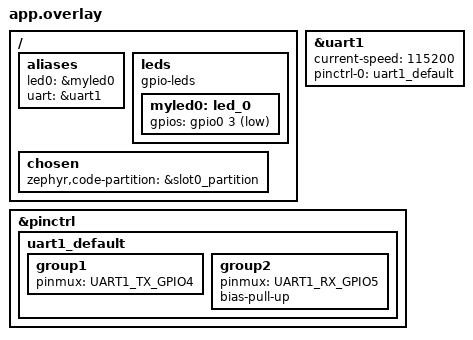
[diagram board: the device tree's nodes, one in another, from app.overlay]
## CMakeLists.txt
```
cmake_minimum_required(VERSION 3.20.0)
find_package(Zephyr REQUIRED HINTS $ENV{ZEPHYR_BASE})
project(ahu)

include_directories(
        src
        ../../oslib/ahu_drivers/ahu_pin_ctrl
	../../oslib/ahu_drivers/ahu_hci
	../../oslib/ahu_drivers/ahu_uart
)

target_sources(app PRIVATE 
	src/main.c 
	src/all.c
	src/time.c
	src/led_module.c
	src/rgb_module.c
	src/pushbutton.c
	src/hts221.c
	src/lps22.c
	src/lsm6dsl.c
	src/sample.c
        ../../oslib/ahu_drivers/ahu_pin_ctrl/pin_ctrl.c
        ../../oslib/ahu_drivers/ahu_hci/ahu_hci.c
        ../../oslib/ahu_drivers/ahu_uart/ahu_uart.c
)
```

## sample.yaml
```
sample:
  name: Prac1
```

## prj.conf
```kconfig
CONFIG_GPIO=y
CONFIG_SHELL=y

CONFIG_SERIAL=y
CONFIG_UART_INTERRUPT_DRIVEN=y

CONFIG_CONSOLE_SUBSYS=y
CONFIG_CONSOLE_GETCHAR=y



CONFIG_LOG=y
CONFIG_LOG_MODE_DEFERRED=y
CONFIG_LOG_RUNTIME_FILTERING=y
CONFIG_LOG_BUFFER_SIZE=2048
CONFIG_LOG_PRINTK=y
CONFIG_LOG_PROCESS_TRIGGER_THRESHOLD=0
CONFIG_COVERAGE=n
CONFIG_LOG_TAG_MAX_LEN=8

CONFIG_UART_LINE_CTRL=y
CONFIG_SHELL_PROMPT_UART="CSSE4011:~$ "
CONFIG_SHELL_CMDS=y
CONFIG_SHELL_TAB=y
CONFIG_SHELL_TAB_AUTOCOMPLETION=y
CONFIG_SHELL_VT100_COLORS=y

CONFIG_CBPRINTF_FP_SUPPORT=y

#CONFIG_FPU=y
#CONFIG_FPU_SHARING=y
#CONFIG_BOOTLOADER_MCUBOOT=y
```

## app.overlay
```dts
/ {
     aliases {
             led0 = &myled0;
     };

     leds {
             compatible = "gpio-leds";
             myled0: led_0 {
                     gpios = <&gpio0 3 GPIO_ACTIVE_LOW>;
             };
     };
};


/ {
	aliases {
		uart = &uart1;
	};
};

&uart1 {
	status = "okay";
	current-speed = <115200>;
	pinctrl-0 = <&uart1_default>;
	pinctrl-names = "default";
};

&pinctrl {
	uart1_default: uart1_default {
		group1 {
			pinmux = <UART1_TX_GPIO4>;
		};
		group2 {
			pinmux = <UART1_RX_GPIO5>;
			bias-pull-up;
		};
	};
};


/ {
   chosen {
      zephyr,code-partition = &slot0_partition;
   };
};
```

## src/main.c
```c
#include <zephyr/kernel.h>
#include <zephyr/device.h>
#include <zephyr/drivers/gpio.h>
#include <zephyr/drivers/uart.h>
#include <zephyr/shell/shell.h>
#include <zephyr/logging/log.h>
#include <zephyr/sys/printk.h>
#include <zephyr/console/console.h>
#include <stdlib.h>

#include "time.h"
#include "pushbutton.h"
#include "lsm6dsl.h"
#include "hts221.h"
#include "lps22.h"
#include "led_module.h"
#include "rgb_module.h"
#include "ahu_uart.h"
#include "sample.h"
#include "all.h"
#include "pin_ctrl.h"
#include "ahu_hci.h"

// SHELL THREAD PARAMS
#define SHELL_STACKSIZE 128
#define SHELL_PRIORITY 6

int is_red_on = 0;
int is_green_on = 0;
int is_blue_on = 0;

int red_toggle = 0;
int green_toggle = 0;
int blue_toggle = 0;

int led1_toggle = 0;
int led2_toggle = 0;

int sample_rate = 1;
double measurement = 0;
int device_id = 0;
int all = 0;

void ahu_shell_thread(void) {
    cmd_all_init();
    cmd_led_init();
    cmd_time_init();
    cmd_rgb_init();
    cmd_pb_init();
    cmd_lsm6dsl_init();
    cmd_lps22_init();
    cmd_hts221_init();
    cmd_sample_rate_init();
    
    while (1) {
        k_usleep(1);
    }
}

K_THREAD_DEFINE(rgb_toggle_id, RGB_STACKSIZE, rgb_toggle_thread, NULL, NULL, NULL, RGB_PRIORITY, 0, 0);

K_THREAD_DEFINE(ahu_shell_thread_id, SHELL_STACKSIZE, ahu_shell_thread, NULL, NULL, NULL, SHELL_PRIORITY, 0, 0);

K_THREAD_DEFINE(uart_thread_id, UART_STACKSIZE, uart_thread, NULL, NULL, NULL, UART_PRIORITY, 0, 0);

// MAIN
void main(void) {
    
    while (1) {
        k_msleep(DELAY);
    }
    
}
```

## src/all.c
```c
#include <zephyr/kernel.h>
#include <zephyr/device.h>
#include <zephyr/drivers/gpio.h>
#include <zephyr/shell/shell.h>
#include <zephyr/logging/log.h>

#include "ahu_hci.h"
#include "ahu_uart.h"
#include "all.h"

// LOG MODULE
LOG_MODULE_REGISTER(all);

extern double measurement;
extern int device_id;
extern int all;

int cmd_all(const struct shell* shell, size_t argc, char** argv) {
    char msg[4] = {0};
    if (argv[1][0] == 'o') {
    
        hci_all(1, msg);
        uart_send_msg32(msg);
        
    	LOG_INF("on\n");
    	
    	k_msleep(1000);
    	all = 1;

    } else if (argv[1][0] == 'f') {
    
        hci_all(0, msg);
        uart_send_msg32(msg);
    
        all = 0;
        LOG_INF("off\n");
    } else {
    	LOG_ERR("invalid command\n");
    }
    return 0;
}

void cmd_all_init(void) {
    SHELL_CMD_ARG_REGISTER(all, NULL, "all <o, f>", cmd_all, 2, 0);
}
```

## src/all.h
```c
#ifndef ALL_H
#define ALL_H

#include <zephyr/kernel.h>
#include <zephyr/device.h>
#include <zephyr/drivers/gpio.h>
#include <zephyr/shell/shell.h>
#include <zephyr/logging/log.h>

/* Function Prototypes..*/
int cmd_all(const struct shell* shell, size_t argc, char** argv);
void cmd_all_init(void);

#endif
```

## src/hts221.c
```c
#include <zephyr/kernel.h>
#include <zephyr/device.h>
#include <zephyr/drivers/gpio.h>
#include <zephyr/shell/shell.h>
#include <zephyr/logging/log.h>

#include "hts221.h"

#include "ahu_hci.h"
#include "ahu_uart.h"

// LOG MODULE
LOG_MODULE_REGISTER(hts221);

float temperature = 30.2;

extern double measurement;

int cmd_hts221(const struct shell* shell, size_t argc, char** argv) {
    char msg[3] = {0};
    if (argv[1][0] == 'r') {
        hci_sensor(HTS221_TEMP, msg);
        uart_send_msg24(msg);
        
        k_msleep(DELAY);
    	LOG_INF("temperature: %f C\n", measurement);
    } else {
    	LOG_ERR("invalid command\n");
    }
    return 0;
}

void cmd_hts221_init(void) {
    SHELL_CMD_ARG_REGISTER(hts221, NULL, "hts221 <r>", cmd_hts221, 2, 0);
}
```

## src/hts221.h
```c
#ifndef HTS221_H
#define HTS221_H

#include <zephyr/kernel.h>
#include <zephyr/device.h>
#include <zephyr/drivers/gpio.h>
#include <zephyr/shell/shell.h>
#include <zephyr/logging/log.h>

/* Function Prototypes..*/
int cmd_hts221(const struct shell* shell, size_t argc, char** argv);
void cmd_hts221_init(void);

#endif
```

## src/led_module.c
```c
#include <zephyr/kernel.h>
#include <zephyr/device.h>
#include <zephyr/drivers/gpio.h>
#include <zephyr/shell/shell.h>
#include <zephyr/logging/log.h>
#include <stdlib.h>
#include "ahu_hci.h"
#include "ahu_uart.h"
#include "pin_ctrl.h"
#include "led_module.h"

#define LED1 1
#define LED2 2

static int is_led1_on = 0;
static int is_led2_on = 0;

extern int led1_toggle;
extern int led2_toggle;

// LOG MODULE
LOG_MODULE_REGISTER(led_module);

void led_error(void) {
    LOG_ERR("invalid command\n");
}

void led1_ctrl(int on) {
    if (on) {
        pin_on(7);
    } else {
        pin_off(7);
    }
}

void led2_ctrl(int on) {
    if (on) {
        pin_on(9);
    } else {
        pin_off(9);
    }
}

// SHELL CMD CALLBACKS
int cmd_led_on(int led) {
    char msg[4] = {0};
    switch(led) {
	case LED1:
	    led1_toggle = 0;
	    if (is_led1_on) {
	    	LOG_WRN("led 1 is already on\n");
	    } else {
		led1_ctrl(1);
		
		hci_led(1, 1, msg);
		uart_send_msg32(msg);
		
		LOG_INF("led 1 is on\n");
	 	
	    }
	    is_led1_on = 1;
	    break;
	case LED2:
	    led2_toggle = 0;
	    if (is_led2_on) {
	    	LOG_WRN("led 2 is already on\n");
	    } else {
	        led2_ctrl(1);
	       
	        hci_led(2, 1, msg);
	        uart_send_msg32(msg);
	        
		LOG_INF("led 2 is on\n");
	    }
	    is_led2_on = 1;
	    break;
	default:
	    LOG_ERR("invalid led\n");
	    break;
    }
    return 0;
}

int cmd_led_off(int led) {
    char msg[4] = {0};
    switch(led) {
	case LED1:
	    led1_toggle = 0;
	    if (!is_led1_on) {
	    	LOG_WRN("led 1 is already off\n");
	    } else {
		led1_ctrl(0);
		
		hci_led(1, 0, msg);
		uart_send_msg32(msg);
		
		LOG_INF("led 1 is off\n");
	    }
	    is_led1_on = 0;
	    break;
	case LED2:
	    led2_toggle = 0;
	    if (!is_led2_on) {
	    	LOG_WRN("led 2 is already off\n");
	    } else {
		led2_ctrl(0);
		
		hci_led(2, 0, msg);
		uart_send_msg32(msg);
		
		LOG_INF("led 2 is off\n");
	    }
	    is_led2_on = 0;
	    break;
	default:
	    LOG_ERR("invalid led\n");
	    break;
    }
    return 0;
}

int cmd_led_toggle(int led) {
    char msg[4] = {0};
    switch(led) {
	case LED1:
	    led1_toggle = 1;
	    is_led1_on = 1 - is_led1_on;
	    
	    hci_led(1, 2, msg);
	    uart_send_msg32(msg);
	    
	    LOG_INF("led 1 toggled\n");
	    break;
	case LED2:
	    led2_toggle = 1;
	    is_led2_on = 1 - is_led2_on;
	    
	    hci_led(2, 2, msg);
	    uart_send_msg32(msg);
	    
	    LOG_INF("led 2 toggled\n");
	    break;
	default:
	    LOG_ERR("invalid led\n");
	    break;
    }
    return 0;
}

int cmd_led(const struct shell* shell, size_t argc, char** argv) {
    if (argv[1][0] != 'w') {
    	led_error();
    } else {
    	if (argv[2][0] == 'o') {
    	    cmd_led_on(atoi(argv[3]));
    	} else if (argv[2][0] == 'f') {
    	    cmd_led_off(atoi(argv[3]));
    	} else if (argv[2][0] == 't') {
    	    cmd_led_toggle(atoi(argv[3]));
    	} else {
    	    led_error();
    	}
    }
    return 0;
}

void cmd_led_init(void) {
    pin_init(LED1);
    pin_init(LED2);
    
    LOG_DBG("led init OK\n");
    
    SHELL_CMD_ARG_REGISTER(led, NULL, "led w <o, f, t> <1, 2>", cmd_led, 4, 0);
    
    /*SHELL_STATIC_SUBCMD_SET_CREATE(
            led_cmds,
            SHELL_CMD_ARG(o, NULL, "led on\n", cmd_led_on, 1, 0),
            SHELL_CMD_ARG(f, NULL, "led off\n", cmd_led_off, 1, 0),
            SHELL_SUBCMD_SET_END
    );
    SHELL_CMD_REGISTER(led, &led_cmds, "led", NULL);*/
}
```

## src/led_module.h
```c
#ifndef LED_MODULE_H
#define LED_MODULE_H

#include <zephyr/kernel.h>
#include <zephyr/device.h>
#include <zephyr/drivers/gpio.h>
#include <zephyr/shell/shell.h>
#include <zephyr/logging/log.h>

/* Function Prototypes..*/
int cmd_led(const struct shell* shell, size_t argc, char** argv);
void cmd_led_init(void);

void led1_ctrl(int);
void led2_ctrl(int);


#endif
```

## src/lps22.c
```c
#include <zephyr/kernel.h>
#include <zephyr/device.h>
#include <zephyr/drivers/gpio.h>
#include <zephyr/shell/shell.h>
#include <zephyr/logging/log.h>

#include "lps22.h"

#include "ahu_hci.h"
#include "ahu_uart.h"

// LOG MODULE
LOG_MODULE_REGISTER(lps22);

float air_pressure = 1.09;

extern double measurement;

int cmd_lps22(const struct shell* shell, size_t argc, char** argv) {
    char msg[3] = {0};
    if (argv[1][0] == 'r') {
        hci_sensor(LPS22_AIR_PRESSURE, msg);
        uart_send_msg24(msg);
        
        k_msleep(DELAY);
    	LOG_INF("air pressure: %f kPa\n", measurement);
    } else {
    	LOG_ERR("invalid command\n");
    }
    return 0;
}

void cmd_lps22_init(void) {
    SHELL_CMD_ARG_REGISTER(lps22, NULL, "lps22 <r>", cmd_lps22, 2, 0);
}
```

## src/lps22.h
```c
#ifndef LPS22_H
#define LPS22_H

#include <zephyr/kernel.h>
#include <zephyr/device.h>
#include <zephyr/drivers/gpio.h>
#include <zephyr/shell/shell.h>
#include <zephyr/logging/log.h>

/* Function Prototypes..*/
int cmd_lps22(const struct shell* shell, size_t argc, char** argv);
void cmd_lps22_init(void);

#endif
```

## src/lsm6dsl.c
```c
#include <zephyr/kernel.h>
#include <zephyr/device.h>
#include <zephyr/drivers/gpio.h>
#include <zephyr/shell/shell.h>
#include <zephyr/logging/log.h>
#include "ahu_hci.h"
#include "ahu_uart.h"
#include "pushbutton.h"

// LOG MODULE
LOG_MODULE_REGISTER(lsm6dsl);

float acceleration = 9.8;
float magnetometer = 0.2;
float gyroscope = 4.9;

extern double measurement;

void get_accelerometer_reading(char axis) {
    char msg[3] = {0};
    if (axis == 'x') {
        hci_sensor(LSM6DSL_ACC_X, msg);
        uart_send_msg24(msg);
        
        k_msleep(DELAY);
        LOG_INF("accelerometer x: %f m/s^2\n", measurement);
        
    } else if (axis == 'y') {
        hci_sensor(LSM6DSL_ACC_Y, msg);
        uart_send_msg24(msg);
        
        k_msleep(DELAY);
        LOG_INF("accelerometer y: %f m/s^2\n", measurement);
        
    } else if (axis == 'z') {
    	hci_sensor(LSM6DSL_ACC_Z, msg);
        uart_send_msg24(msg);
        
        k_msleep(DELAY);
        LOG_INF("accelerometer z: %f m/s^2\n", measurement);
        
    } else {
        LOG_ERR("invalid axis\n");
    }
}

void get_gyroscope_reading(char axis) {
    char msg[3] = {0};
    if (axis == 'x') {
        hci_sensor(LSM6DSL_GYR_X, msg);
        uart_send_msg24(msg);
        
        k_msleep(DELAY);
        LOG_INF("gyroscope x: %f dps\n", measurement);
        
    } else if (axis == 'y') {
        hci_sensor(LSM6DSL_GYR_Y, msg);
        uart_send_msg24(msg);
        
        k_msleep(DELAY);
        LOG_INF("gyroscope y: %f dps\n", measurement);
        
    } else if (axis == 'z') {
        hci_sensor(LSM6DSL_GYR_Z, msg);
        uart_send_msg24(msg);
        
        k_msleep(DELAY);
        LOG_INF("gyroscope z: %f dps\n", measurement);
        
    } else {
        LOG_ERR("invalid axis\n");
    }
}

void get_magnetometer_reading(char axis) {
    char msg[3] = {0};
    if (axis == 'x') {
        hci_sensor(LSM6DSL_MAG_X, msg);
        uart_send_msg24(msg);
        
        k_msleep(DELAY);
        LOG_INF("magnetometer x: %f gauss\n", measurement);
        
    } else if (axis == 'y') {
        hci_sensor(LSM6DSL_MAG_Y, msg);
        uart_send_msg24(msg);
        
        k_msleep(DELAY);
        LOG_INF("magnetometer y: %f gauss\n", measurement);
        
    } else if (axis == 'z') {
        hci_sensor(LSM6DSL_MAG_Z, msg);
        uart_send_msg24(msg);
        
        k_msleep(DELAY);
        LOG_INF("magnetometer z: %f gauss\n", measurement);
    } else {
        LOG_ERR("invalid axis\n");
    }
}

int cmd_lsm6dsl(const struct shell* shell, size_t argc, char** argv) {
    if (argv[1][0] == 'r') {
    	if (argv[2][0] == 'a') {
    	    get_accelerometer_reading(argv[3][0]);
    	} else if (argv[2][0] == 'g') {
    	    get_gyroscope_reading(argv[3][0]);
    	} else if (argv[2][0] == 'm') {
    	    get_magnetometer_reading(argv[3][0]);
    	} else {
    	    LOG_ERR("invalid sensor\n");
    	}
    } else {
    	LOG_ERR("invalid command\n");
    }
    return 0;
}

void cmd_lsm6dsl_init(void) {
    SHELL_CMD_ARG_REGISTER(lsm6dsl, NULL, "lsm6dsl <r> <a, g, m> <x, y, z>", cmd_lsm6dsl, 4, 0);
}
```

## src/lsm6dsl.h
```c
#ifndef LSM6DSL_H
#define LSM6DSL_H

#include <zephyr/kernel.h>
#include <zephyr/device.h>
#include <zephyr/drivers/gpio.h>
#include <zephyr/shell/shell.h>
#include <zephyr/logging/log.h>

/* Function Prototypes..*/
int cmd_lsm6dsl(const struct shell* shell, size_t argc, char** argv);
void cmd_lsm6dsl_init(void);

#endif
```

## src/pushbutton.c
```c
#include <zephyr/kernel.h>
#include <zephyr/device.h>
#include <zephyr/drivers/gpio.h>
#include <zephyr/shell/shell.h>
#include <zephyr/logging/log.h>
#include "ahu_hci.h"
#include "ahu_uart.h"
#include "pushbutton.h"

// LOG MODULE
LOG_MODULE_REGISTER(pb);

extern double measurement;

int cmd_pb(const struct shell* shell, size_t argc, char** argv) {
    char msg[3] = {0};
    if (argv[1][0] == 'r') {
        hci_sensor(PB_STATE, msg);
        uart_send_msg24(msg);
    
        k_msleep(DELAY);
    	LOG_INF("%f\n", measurement);
    	
    } else {
    	LOG_ERR("invalid command\n");
    }
    return 0;
}

void cmd_pb_init(void) {
    SHELL_CMD_ARG_REGISTER(pb, NULL, "pb <r>", cmd_pb, 2, 0);
}
```

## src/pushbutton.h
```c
#ifndef PUSHBUTTON_H
#define PUSHBUTTON_H

#include <zephyr/kernel.h>
#include <zephyr/device.h>
#include <zephyr/drivers/gpio.h>
#include <zephyr/shell/shell.h>
#include <zephyr/logging/log.h>

/* Function Prototypes..*/
int cmd_pb(const struct shell* shell, size_t argc, char** argv);
void cmd_pb_init(void);

#endif
```
